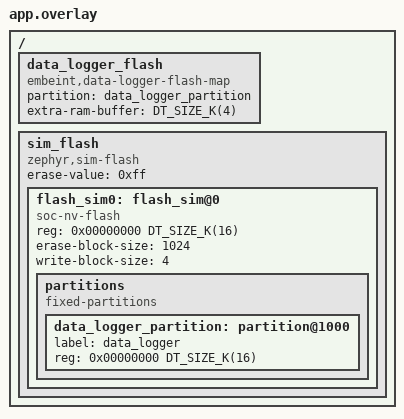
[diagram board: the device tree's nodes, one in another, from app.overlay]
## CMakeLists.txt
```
# SPDX-License-Identifier: Apache-2.0

cmake_minimum_required(VERSION 3.20.0)
find_package(Zephyr REQUIRED HINTS $ENV{ZEPHYR_BASE})
project(ram_buffering)

target_sources(app PRIVATE
  src/main.c
)
```

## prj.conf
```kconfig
CONFIG_ZTEST=y
CONFIG_FLASH=y
CONFIG_FLASH_SIMULATOR=y
CONFIG_FLASH_SIMULATOR_UNALIGNED_READ=y
CONFIG_FLASH_MAP=y
CONFIG_DATA_LOGGER=y
CONFIG_DATA_LOGGER_FLASH_MAP=y
CONFIG_DATA_LOGGER_RAM_BUFFER=y
```

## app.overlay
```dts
#include <mem.h>

/ {
	data_logger_flash: data_logger_flash {
		compatible = "embeint,data-logger-flash-map", "embeint,data-logger";
		partition = <&data_logger_partition>;
		extra-ram-buffer = <DT_SIZE_K(4)>;
	};

	sim_flash: sim_flash {
		compatible = "zephyr,sim-flash";

		#address-cells = <1>;
		#size-cells = <1>;
		erase-value = <0xff>;

		flash_sim0: flash_sim@0 {
			compatible = "soc-nv-flash";
			reg = <0x00000000 DT_SIZE_K(16)>;

			erase-block-size = <1024>;
			write-block-size = <4>;

			partitions {
				compatible = "fixed-partitions";
				#address-cells = <1>;
				#size-cells = <1>;

				data_logger_partition: partition@1000 {
					label = "data_logger";
					reg = <0x00000000 DT_SIZE_K(16)>;
				};
			};
		};
	};
};
```

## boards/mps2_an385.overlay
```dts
#include <mem.h>

/delete-node/ &sim_flash_controller;

#include "../app.overlay"
```

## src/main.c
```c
/**
 * @file
 * @copyright 2024 Embeint Holdings Pty Ltd
 * @author Jordan Yates <jordan@embeint.com>
 *
 * SPDX-License-Identifier: FSL-1.1-ALv2
 */

#include <string.h>

#include <zephyr/ztest.h>
#include <zephyr/kernel.h>

#include <infuse/data_logger/logger.h>

static uint8_t input_buffer[1024] = {0};
static uint8_t output_buffer[1024];

ZTEST(data_logger_ram_buffering, test_basic_buffer)
{
	const struct device *logger = DEVICE_DT_GET(DT_NODELABEL(data_logger_flash));
	struct data_logger_persistent_block_header *hdr = (void *)output_buffer;
	struct data_logger_state state;
	int rc;

	data_logger_get_state(logger, &state);

	/* 4kB buffer, 512 byte blocks (minus alignment testing), expect 7 blocks pending before any
	 * flush
	 */
	for (int i = 0; i < 7; i++) {
		/* Write block to logger */
		rc = data_logger_block_write(logger, 0x75 + i, input_buffer, state.block_size - i);
		zassert_equal(0, rc);

		data_logger_get_state(logger, &state);
		zassert_equal(0, state.current_block);
	}
	/* 8th block should trigger the flush of the 7 pended plus this */
	zassert_equal(0, data_logger_block_write(logger, 0x75 + 7, input_buffer, state.block_size));
	data_logger_get_state(logger, &state);
	zassert_equal(8, state.current_block);

	/* Read data back */
	for (int i = 0; i < 8; i++) {
		rc = data_logger_block_read(logger, i, 0, output_buffer, state.block_size);
		zassert_equal(0, rc);
		zassert_equal(0x75 + i, hdr->block_type);
	}

	/* Write two blocks to logger */
	zassert_equal(0, data_logger_block_write(logger, 0x75, input_buffer, state.block_size));
	zassert_equal(0, data_logger_block_write(logger, 0x76, input_buffer, state.block_size));
	k_sleep(K_TICKS(1));
	data_logger_get_state(logger, &state);
	zassert_equal(8, state.current_block);

	/* Run the flush command */
	zassert_equal(0, data_logger_flush(logger));
	k_sleep(K_TICKS(1));
	data_logger_get_state(logger, &state);
	zassert_equal(10, state.current_block);

	/* Data should exist on the backend */
	zassert_equal(0, data_logger_block_read(logger, 8, 0, output_buffer, state.block_size));
	zassert_equal(1, hdr->block_wrap);
	zassert_equal(0x75, hdr->block_type);
	zassert_equal(0, data_logger_block_read(logger, 9, 0, output_buffer, state.block_size));
	zassert_equal(1, hdr->block_wrap);
	zassert_equal(0x76, hdr->block_type);

	/* Run the flush command again, nothing should happen */
	zassert_equal(0, data_logger_flush(logger));
	k_sleep(K_TICKS(1));
	data_logger_get_state(logger, &state);
	zassert_equal(10, state.current_block);
}

static void erase_progress(uint32_t blocks_erased)
{
	ARG_UNUSED(blocks_erased);
}

ZTEST(data_logger_ram_buffering, test_erase_discards_buffer)
{
	const struct device *logger = DEVICE_DT_GET(DT_NODELABEL(data_logger_flash));
	struct data_logger_state state;

	zassert_equal(0, data_logger_erase(logger, false, erase_progress));
	data_logger_get_state(logger, &state);
	zassert_equal(0, state.current_block);

	/* Two blocks pending in the RAM buffer */
	zassert_equal(0, data_logger_block_write(logger, 0x75, input_buffer, state.block_size));
	zassert_equal(0, data_logger_block_write(logger, 0x76, input_buffer, state.block_size));
	data_logger_get_state(logger, &state);
	zassert_equal(0, state.current_block);

	/* Erasing the logger also erases the pending data */
	zassert_equal(0, data_logger_erase(logger, false, erase_progress));
	zassert_equal(0, data_logger_flush(logger));
	data_logger_get_state(logger, &state);
	zassert_equal(0, state.current_block);

	/* Logger continues to work */
	zassert_equal(0, data_logger_block_write(logger, 0x77, input_buffer, state.block_size));
	zassert_equal(0, data_logger_flush(logger));
	data_logger_get_state(logger, &state);
	zassert_equal(1, state.current_block);
}

ZTEST_SUITE(data_logger_ram_buffering, NULL, NULL, NULL, NULL, NULL);
```
